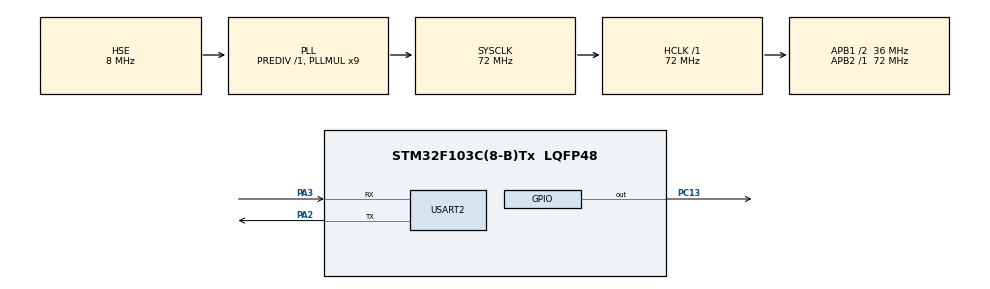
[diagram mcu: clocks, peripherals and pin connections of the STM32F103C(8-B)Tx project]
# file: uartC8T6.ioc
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Dma.Request0=USART2_RX
Dma.USART2_RX.0.Direction=DMA_PERIPH_TO_MEMORY
Dma.USART2_RX.0.Instance=DMA1_Channel6
Dma.USART2_RX.0.MemDataAlignment=DMA_MDATAALIGN_BYTE
Dma.USART2_RX.0.MemInc=DMA_MINC_ENABLE
Dma.USART2_RX.0.Mode=DMA_NORMAL
Dma.USART2_RX.0.PeriphDataAlignment=DMA_PDATAALIGN_BYTE
Dma.USART2_RX.0.PeriphInc=DMA_PINC_DISABLE
Dma.USART2_RX.0.Priority=DMA_PRIORITY_LOW
Mcu.Family=STM32F1
Mcu.Name=STM32F103C(8-B)Tx
Mcu.Package=LQFP48
NVIC.DMA1_Channel6_IRQn=true\:0\:0\:false\:false\:true\:false\:true\:true
NVIC.PriorityGroup=NVIC_PRIORITYGROUP_4
NVIC.USART2_IRQn=true\:0\:0\:false\:false\:true\:true\:true\:true
PA13.Mode=Serial_Wire
PA13.Signal=SYS_JTMS-SWDIO
PA14.Mode=Serial_Wire
PA14.Signal=SYS_JTCK-SWCLK
PA2.Mode=Asynchronous
PA2.Signal=USART2_TX
PA3.Mode=Asynchronous
PA3.Signal=USART2_RX
PC13-TAMPER-RTC.GPIO_ModeDefaultOutputPP=GPIO_MODE_OUTPUT_PP
PC13-TAMPER-RTC.GPIO_PuPd=GPIO_PULLUP
PC13-TAMPER-RTC.Signal=GPIO_Output
PC14-OSC32_IN.Mode=LSE-External-Oscillator
PC14-OSC32_IN.Signal=RCC_OSC32_IN
PC15-OSC32_OUT.Mode=LSE-External-Oscillator
PC15-OSC32_OUT.Signal=RCC_OSC32_OUT
PD0-OSC_IN.Mode=HSE-External-Oscillator
PD0-OSC_IN.Signal=RCC_OSC_IN
PD1-OSC_OUT.Mode=HSE-External-Oscillator
PD1-OSC_OUT.Signal=RCC_OSC_OUT
ProjectManager.HeapSize=0x200
ProjectManager.StackSize=0x400
ProjectManager.TargetToolchain=MDK-ARM V5.32
RCC.AHBFreq_Value=72000000
RCC.APB1CLKDivider=RCC_HCLK_DIV2
RCC.APB1Freq_Value=36000000
RCC.APB1TimFreq_Value=72000000
RCC.APB2Freq_Value=72000000
RCC.APB2TimFreq_Value=72000000
RCC.HCLKFreq_Value=72000000
RCC.PLLMUL=RCC_PLL_MUL9
RCC.PLLSourceVirtual=RCC_PLLSOURCE_HSE
RCC.SYSCLKFreq_VALUE=72000000
RCC.SYSCLKSource=RCC_SYSCLKSOURCE_PLLCLK
RCC.USBFreq_Value=72000000
USART2.VirtualMode=VM_ASYNC
board=custom

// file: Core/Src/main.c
/* USER CODE BEGIN Header */
/**
 ******************************************************************************
 * @file           : main.c
 * @brief          : Main program body
 ******************************************************************************
 * @attention
 *
 * Copyright (c) 2024 STMicroelectronics.
 * All rights reserved.
 *
 * This software is licensed under terms that can be found in the LICENSE file
 * in the root directory of this software component.
 * If no LICENSE file comes with this software, it is provided AS-IS.
 *
 ******************************************************************************
 */
/* USER CODE END Header */
#include "main.h"
#include "dma.h"
#include "usart.h"
#include "gpio.h"

/* USER CODE BEGIN PV */
  uint8_t RxData[10];
  uint8_t TxData[5];
/* USER CODE END PV */

void SystemClock_Config(void);
/* USER CODE BEGIN PFP */

void Float_to_U8(float FLoTin, uint8_t *U8out);
/* USER CODE END PFP */

int main(void)
{

  /* MCU Configuration--------------------------------------------------------*/

  /* Reset of all peripherals, Initializes the Flash interface and the Systick. */
  HAL_Init();

  /* USER CODE BEGIN Init */
  float test_Float = 3.1415;

  /* USER CODE END Init */

  /* Configure the system clock */
  SystemClock_Config();

  /* Initialize all configured peripherals */
  MX_GPIO_Init();
  MX_DMA_Init();
  MX_USART2_UART_Init();
  /* USER CODE BEGIN 2 */
  HAL_UART_Receive_IT(&huart2, RxData, 5);
  LED0(1);
  Float_to_U8(test_Float,TxData);
  /* USER CODE END 2 */

  /* Infinite loop */
  while (1)
  {

    /* USER CODE BEGIN 3 */
    HAL_UART_Transmit_IT(&huart2,TxData,4);
    HAL_Delay(10000);
  }
  /* USER CODE END 3 */
}

void SystemClock_Config(void)
{
  RCC_OscInitTypeDef RCC_OscInitStruct = {0};
  RCC_ClkInitTypeDef RCC_ClkInitStruct = {0};

  /** Initializes the RCC Oscillators according to the specified parameters
   * in the RCC_OscInitTypeDef structure.
   */
  RCC_OscInitStruct.OscillatorType = RCC_OSCILLATORTYPE_HSE;
  RCC_OscInitStruct.HSEState = RCC_HSE_ON;
  RCC_OscInitStruct.HSEPredivValue = RCC_HSE_PREDIV_DIV1;
  RCC_OscInitStruct.HSIState = RCC_HSI_ON;
  RCC_OscInitStruct.PLL.PLLState = RCC_PLL_ON;
  RCC_OscInitStruct.PLL.PLLSource = RCC_PLLSOURCE_HSE;
  RCC_OscInitStruct.PLL.PLLMUL = RCC_PLL_MUL9;
  if (HAL_RCC_OscConfig(&RCC_OscInitStruct) != HAL_OK)
  {
    Error_Handler();
  }

  /** Initializes the CPU, AHB and APB buses clocks
   */
  RCC_ClkInitStruct.ClockType = RCC_CLOCKTYPE_HCLK | RCC_CLOCKTYPE_SYSCLK | RCC_CLOCKTYPE_PCLK1 | RCC_CLOCKTYPE_PCLK2;
  RCC_ClkInitStruct.SYSCLKSource = RCC_SYSCLKSOURCE_PLLCLK;
  RCC_ClkInitStruct.AHBCLKDivider = RCC_SYSCLK_DIV1;
  RCC_ClkInitStruct.APB1CLKDivider = RCC_HCLK_DIV2;
  RCC_ClkInitStruct.APB2CLKDivider = RCC_HCLK_DIV1;

  if (HAL_RCC_ClockConfig(&RCC_ClkInitStruct, FLASH_LATENCY_2) != HAL_OK)
  {
    Error_Handler();
  }
}

/* USER CODE BEGIN 4 */
void Float_to_U8(float FLin, uint8_t *U8out)
{
  uint32_t mid = (uint32_t)(FLin);
  U8out[0] = (mid >> 24) & 0xff;
  U8out[1] = (mid >> 16) & 0xff;
  U8out[2] = (mid >> 8) & 0xff;
  U8out[3] = (mid >> 0) & 0xff;
}
float U8_to_Float(float* FLout, uint8_t *U8in)
{
  uint32_t mid = (U8in[0] << 24) | (U8in[1] << 16) | (U8in[2] << 8) | U8in[3];
  return (float)(mid);
}
void HAL_UART_RxCpltCallback(UART_HandleTypeDef *huart)
{
  if(huart== & huart2){
    LED0_TOGGLE;
    HAL_UART_Receive_IT(&huart2,RxData,4);
  }
}
/* USER CODE END 4 */

void Error_Handler(void)
{
  __disable_irq();
  while (1)
  {
  }
}
